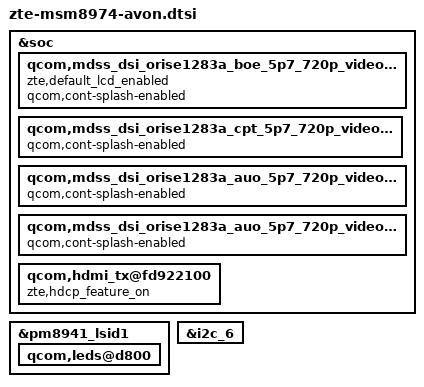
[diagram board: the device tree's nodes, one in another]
/* Copyright (c) 2012-2013, The Linux Foundation. All rights reserved.
 *
 * This program is free software; you can redistribute it and/or modify
 * it under the terms of the GNU General Public License version 2 and
 * only version 2 as published by the Free Software Foundation.
 *
 * This program is distributed in the hope that it will be useful,
 * but WITHOUT ANY WARRANTY; without even the implied warranty of
 * MERCHANTABILITY or FITNESS FOR A PARTICULAR PURPOSE.  See the
 * GNU General Public License for more details.
 */

/include/ "dsi-panel-orise1283a-boe-5p7-720p-video-zte-100.dtsi"
/include/ "dsi-panel-orise1283a-cpt-5p7-720p-video-zte-101.dtsi"
/include/ "dsi-panel-orise1283a-auo-5p7-720p-video-zte-102.dtsi"
/include/ "dsi-panel-orise1283a-auo-5p7-720p-video-zte-103.dtsi"
/include/ "sii8334.dtsi"
/include/ "touch-key-backlight_avon.dtsi"
/*
 * Added for camera sensor & eeprom by ZTE_JIA_20130828 jia.jia
 */
/include/ "msm8974-camera-sensor-mtp-avon.dtsi"
/include/ "msm8974-camera-eeprom-mtp-avon.dtsi"

/include/ "msm8974-adnc-es325.dtsi"

&soc {	
	qcom,mdss_dsi_orise1283a_boe_5p7_720p_video_100{
		status = "ok";
		zte,default_lcd_enabled;
		qcom,cont-splash-enabled;
	};
	
	qcom,mdss_dsi_orise1283a_cpt_5p7_720p_video_101{
		status = "ok";
		qcom,cont-splash-enabled;
	};

	qcom,mdss_dsi_orise1283a_auo_5p7_720p_video_102 {
		status = "ok";
		qcom,cont-splash-enabled;
	};
	
	qcom,mdss_dsi_orise1283a_auo_5p7_720p_video_103 {
		status = "ok";
		qcom,cont-splash-enabled;
	};
	
	qcom,hdmi_tx@fd922100 {
		status = "ok";
		zte,hdcp_feature_on;
	};
	
};

&pm8941_lsid1 {
	qcom,leds@d800 {
		status = "okay";
	};
};

&i2c_6 {  /* jht 20130906 add for nxp nfc */
	status = "ok";
};
